# STM32U585 register map
File version: 1.3
CPU: CM33 r0p1, little endian, MPU, FPU, 4 interrupt priority bits
Registers are 32-bit, read-write, reset 0x0 unless marked. A register's access mark holds for its fields unless they carry their own. Offsets are from the block's base; [hi:lo] are bit positions.

## LPTIM1 — Low power timer
Base 0x46004400
Same registers: LPTIM2 0x40009400, LPTIM3 0x46004800, SEC_LPTIM2 0x50009400, SEC_LPTIM1 0x56004400, SEC_LPTIM3 0x56004800
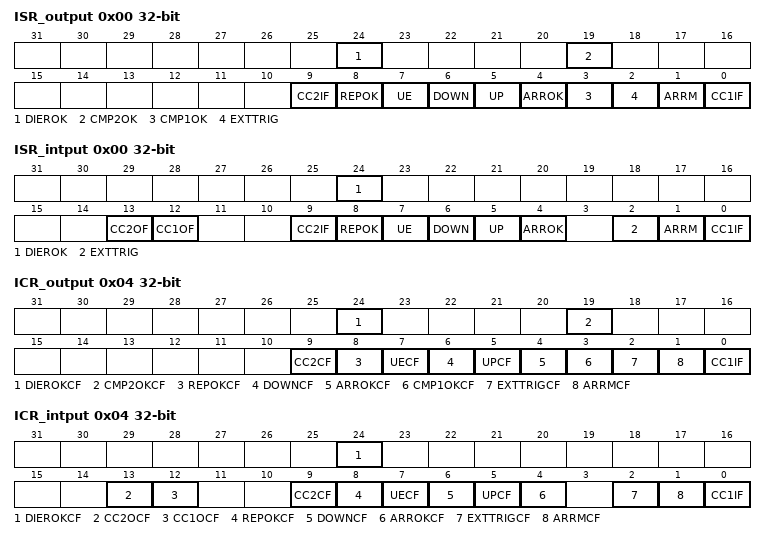
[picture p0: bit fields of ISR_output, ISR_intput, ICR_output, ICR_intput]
0x00 ISR_output ro — Interrupt and Status Register (output mode)
  [24] DIEROK — Interrupt enable register update OK
  [19] CMP2OK — Compare register 2 update OK
  [9] CC2IF — Compare 2 interrupt flag
  [8] REPOK — Repetition register update Ok
  [7] UE — LPTIM update event occurred
  [6] DOWN — Counter direction change up to down
  [5] UP — Counter direction change down to up
  [4] ARROK — Autoreload register update OK
  [3] CMP1OK — Compare register 1 update OK
  [2] EXTTRIG — External trigger edge event
  [1] ARRM — Autoreload match
  [0] CC1IF — Compare 1 interrupt flag
0x00 ISR_intput ro (alternate view of ISR_output) — Interrupt and Status Register (intput mode)
  [24] DIEROK — Interrupt enable register update OK
  [13] CC2OF — Capture 2 over-capture flag
  [12] CC1OF — Capture 1 over-capture flag
  [9] CC2IF — Capture 2 interrupt flag
  [8] REPOK — Repetition register update Ok
  [7] UE — LPTIM update event occurred
  [6] DOWN — Counter direction change up to down
  [5] UP — Counter direction change down to up
  [4] ARROK — Autoreload register update OK
  [2] EXTTRIG — External trigger edge event
  [1] ARRM — Autoreload match
  [0] CC1IF — Compare 1 interrupt flag
0x04 ICR_output wo — Interrupt Clear Register (output mode)
  [24] DIEROKCF — Interrupt enable register update OK clear flag
  [19] CMP2OKCF — Compare register 2 update OK clear flag
  [9] CC2CF — Capture/compare 2 clear flag
  [8] REPOKCF — Repetition register update OK clear flag
  [7] UECF — Update event clear flag
  [6] DOWNCF — Direction change to down Clear Flag
  [5] UPCF — Direction change to UP Clear Flag
  [4] ARROKCF — Autoreload register update OK Clear Flag
  [3] CMP1OKCF — Compare register 1 update OK Clear Flag
  [2] EXTTRIGCF — External trigger valid edge Clear Flag
  [1] ARRMCF — Autoreload match Clear Flag
  [0] CC1IF — Capture/compare 1 clear flag
0x04 ICR_intput wo (alternate view of ICR_output) — Interrupt Clear Register (intput mode)
  [24] DIEROKCF — Interrupt enable register update OK clear flag
  [13] CC2OCF — Capture/compare 2 over-capture clear flag
  [12] CC1OCF — Capture/compare 1 over-capture clear flag
  [9] CC2CF — Capture/compare 2 clear flag
  [8] REPOKCF — Repetition register update OK clear flag
  [7] UECF — Update event clear flag
  [6] DOWNCF — Direction change to down Clear Flag
  [5] UPCF — Direction change to UP Clear Flag
  [4] ARROKCF — Autoreload register update OK Clear Flag
  [2] EXTTRIGCF — External trigger valid edge Clear Flag
  [1] ARRMCF — Autoreload match Clear Flag
  [0] CC1IF — Capture/compare 1 clear flag
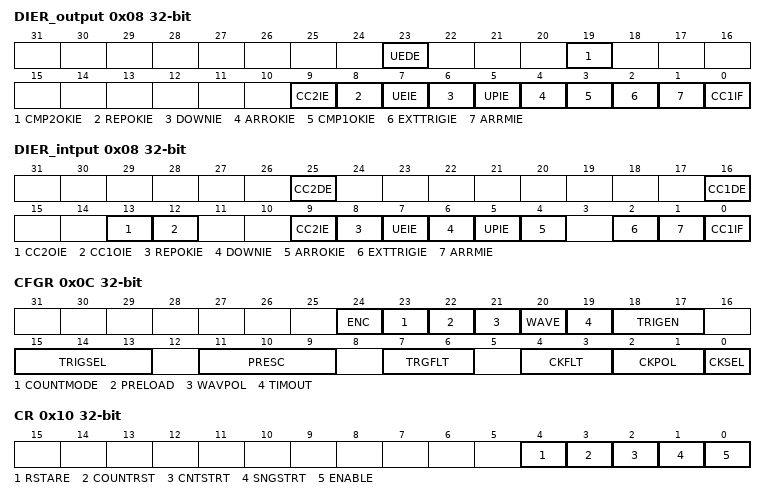
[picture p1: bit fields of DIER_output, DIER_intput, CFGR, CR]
0x08 DIER_output — LPTIM interrupt Enable Register (output mode)
  [23] UEDE — Update event DMA request enable
  [19] CMP2OKIE — Compare register 2 update OK interrupt enable
  [9] CC2IE — Capture/compare 2 interrupt enable
  [8] REPOKIE
  [7] UEIE — Update event interrupt enable
  [6] DOWNIE — Direction change to down Interrupt Enable
  [5] UPIE — Direction change to UP Interrupt Enable
  [4] ARROKIE — Autoreload register update OK Interrupt Enable
  [3] CMP1OKIE — Compare register 1 update OK Interrupt Enable
  [2] EXTTRIGIE — External trigger valid edge Interrupt Enable
  [1] ARRMIE — Autoreload match Interrupt Enable
  [0] CC1IF — Capture/compare 1 clear flag
0x08 DIER_intput (alternate view of DIER_output) — LPTIM interrupt Enable Register (intput mode)
  [25] CC2DE — Capture/compare 2 DMA request enable
  [16] CC1DE — Capture/compare 1 DMA request enable
  [13] CC2OIE — Capture/compare 2 over-capture interrupt enable
  [12] CC1OIE — Capture/compare 1 over-capture interrupt enable
  [9] CC2IE — Capture/compare 2 interrupt enable
  [8] REPOKIE
  [7] UEIE — Update event interrupt enable
  [6] DOWNIE — Direction change to down Interrupt Enable
  [5] UPIE — Direction change to UP Interrupt Enable
  [4] ARROKIE — Autoreload register update OK Interrupt Enable
  [2] EXTTRIGIE — External trigger valid edge Interrupt Enable
  [1] ARRMIE — Autoreload match Interrupt Enable
  [0] CC1IF — Capture/compare 1 clear flag
0x0C CFGR — Configuration Register
  [24] ENC — Encoder mode enable
  [23] COUNTMODE — counter mode enabled
  [22] PRELOAD — Registers update mode
  [21] WAVPOL — Waveform shape polarity
  [20] WAVE — Waveform shape
  [19] TIMOUT — Timeout enable
  [18:17] TRIGEN — Trigger enable and polarity
  [15:13] TRIGSEL — Trigger selector
  [11:9] PRESC — Clock prescaler
  [7:6] TRGFLT — Configurable digital filter for trigger
  [4:3] CKFLT — Configurable digital filter for external clock
  [2:1] CKPOL — Clock Polarity
  [0] CKSEL — Clock selector
0x10 CR — Control Register
  [4] RSTARE — Reset after read enable
  [3] COUNTRST — Counter reset
  [2] CNTSTRT — Timer start in continuous mode
  [1] SNGSTRT — LPTIM start in single mode
  [0] ENABLE — LPTIM Enable
0x14 CCR1 — Compare Register
  [15:0] CCR1 — Capture/compare 1 value
0x18 ARR reset 0x1 — Autoreload Register
  [15:0] ARR — Auto reload value
0x1C CNT ro — Counter Register
  [15:0] CNT — Counter value
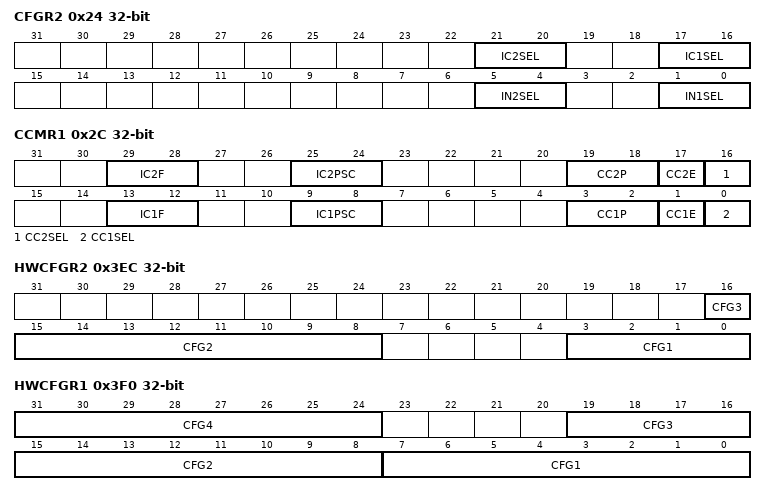
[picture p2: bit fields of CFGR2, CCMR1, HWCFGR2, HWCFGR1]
0x24 CFGR2 — LPTIM configuration register 2
  [21:20] IC2SEL — LPTIM input capture 2 selection
  [17:16] IC1SEL — LPTIM input capture 1 selection
  [5:4] IN2SEL — LPTIM input 2 selection
  [1:0] IN1SEL — LPTIM input 1 selection
0x28 RCR — LPTIM repetition register
  [7:0] REP — Repetition register value
0x2C CCMR1 — LPTIM capture/compare mode register 1
  [29:28] IC2F — Input capture 2 filter
  [25:24] IC2PSC — Input capture 2 prescaler
  [19:18] CC2P — Capture/compare 2 output polarity
  [17] CC2E — Capture/compare 2 output enable
  [16] CC2SEL — Capture/compare 2 selection
  [13:12] IC1F — Input capture 1 filter
  [9:8] IC1PSC — Input capture 1 prescaler
  [3:2] CC1P — Capture/compare 1 output polarity
  [1] CC1E — Capture/compare 1 output enable
  [0] CC1SEL — Capture/compare 1 selection
0x34 CCR2 — LPTIM Compare Register 2
  [15:0] CCR2 — Capture/compare 2 value
0x3EC HWCFGR2 ro — LPTIM peripheral hardware configuration register 2
  [16] CFG3 — peripheral hardware configuration 3
  [15:8] CFG2 — peripheral hardware configuration 2
  [3:0] CFG1 — peripheral hardware configuration 1
0x3F0 HWCFGR1 ro — LPTIM peripheral hardware configuration register 1
  [31:24] CFG4 — peripheral hardware configuration 4
  [19:16] CFG3 — peripheral hardware configuration 3
  [15:8] CFG2 — peripheral hardware configuration 2
  [7:0] CFG1 — peripheral hardware configuration 1

## LPTIM4 — Low power timer
Base 0x46004C00
Same registers: SEC_LPTIM4 0x56004C00
Registers as LPTIM1, without ISR_output, ISR_intput, ICR_output, ICR_intput, DIER_output, DIER_intput; these are added or differ:
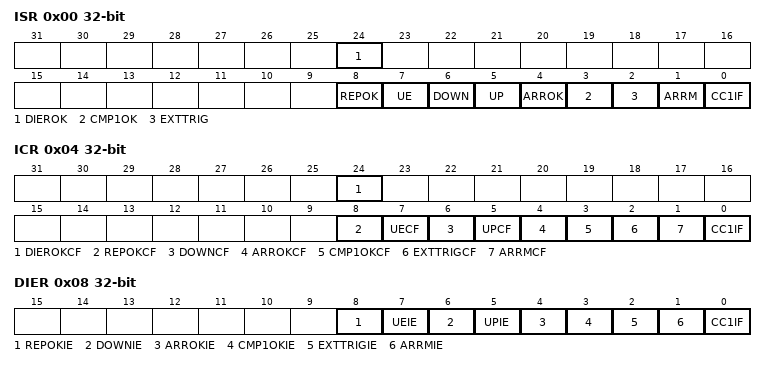
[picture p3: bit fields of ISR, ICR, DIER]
0x00 ISR ro — Interrupt and Status Register
  [24] DIEROK — Interrupt enable register update OK
  [8] REPOK — Repetition register update Ok
  [7] UE — LPTIM update event occurred
  [6] DOWN — Counter direction change up to down
  [5] UP — Counter direction change down to up
  [4] ARROK — Autoreload register update OK
  [3] CMP1OK — Compare register 1 update OK
  [2] EXTTRIG — External trigger edge event
  [1] ARRM — Autoreload match
  [0] CC1IF — Compare 1 interrupt flag
0x04 ICR wo — Interrupt Clear Register
  [24] DIEROKCF — Interrupt enable register update OK clear flag
  [8] REPOKCF — Repetition register update OK clear flag
  [7] UECF — Update event clear flag
  [6] DOWNCF — Direction change to down Clear Flag
  [5] UPCF — Direction change to UP Clear Flag
  [4] ARROKCF — Autoreload register update OK Clear Flag
  [3] CMP1OKCF — Compare register 1 update OK Clear Flag
  [2] EXTTRIGCF — External trigger valid edge Clear Flag
  [1] ARRMCF — Autoreload match Clear Flag
  [0] CC1IF — Capture/compare 1 clear flag
0x08 DIER — LPTIM interrupt Enable Register
  [8] REPOKIE
  [7] UEIE — Update event interrupt enable
  [6] DOWNIE — Direction change to down Interrupt Enable
  [5] UPIE — Direction change to UP Interrupt Enable
  [4] ARROKIE — Autoreload register update OK Interrupt Enable
  [3] CMP1OKIE — Compare register 1 update OK Interrupt Enable
  [2] EXTTRIGIE — External trigger valid edge Interrupt Enable
  [1] ARRMIE — Autoreload match Interrupt Enable
  [0] CC1IF — Capture/compare 1 clear flag
